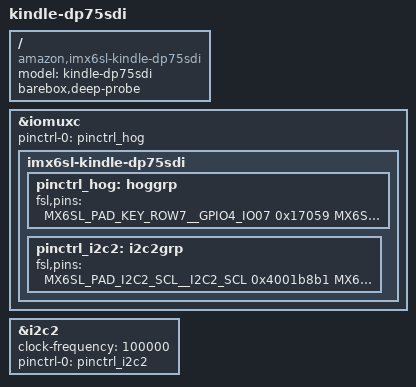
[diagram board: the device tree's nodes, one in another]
// SPDX-License-Identifier: GPL-2.0-or-later
/*
 * Copyright (C) 2025 Alexander Kurz <akurz@blala.de>
 */

/dts-v1/;
#include "imx6sl-kindle-common.dtsi"
#include <dt-bindings/interrupt-controller/irq.h>
#include <dt-bindings/gpio/gpio.h>
#include <dt-bindings/input/input.h>

/ {
	model = "kindle-dp75sdi";
	compatible = "amazon,imx6sl-kindle-dp75sdi",  "fsl,imx6sl";
	barebox,deep-probe;
};

&iomuxc {
	pinctrl-names = "default";
	pinctrl-0 = <&pinctrl_hog>;

	imx6sl-kindle-dp75sdi {
		pinctrl_hog: hoggrp {
			fsl,pins = <
				/* Hall sensor */
				MX6SL_PAD_KEY_ROW7__GPIO4_IO07	0x17059
				/* Touch reset */
				MX6SL_PAD_KEY_ROW6__GPIO4_IO05	0x17059
				/* EMMC_3v2_EN, EMMC_1v8_EN */
				MX6SL_PAD_FEC_RXD0__GPIO4_IO17	0x17059
				MX6SL_PAD_FEC_MDC__GPIO4_IO23	0x17059
				/* WLAN pwd */
				MX6SL_PAD_KEY_ROW2__GPIO3_IO29	0x17059
			>;
		};

		pinctrl_i2c2: i2c2grp {
			fsl,pins = <
				MX6SL_PAD_I2C2_SCL__I2C2_SCL	0x4001b8b1
				MX6SL_PAD_I2C2_SDA__I2C2_SDA	0x4001b8b1
			>;
		};
	};
};

&i2c2 {
	clock-frequency = <100000>;
	pinctrl-names = "default";
	pinctrl-0 = <&pinctrl_i2c2>;
	status = "okay";
};
